VERSION ""

NS_ :

BS_:

BU_: AI JOYSTICK VCU OPUS RES

BO_ 3221225472 VECTOR__INDEPENDENT_SIG_MSG: 0 Vector__XXX
 SG_ VEHFAN_DO_V_UC : 0|1@1- (67,0) [0|67] "DO" Vector__XXX
 SG_ SCUFAN_FB_AI_V_UC : 0|1@1- (19,0) [0|19] "AI" Vector__XXX
 SG_ SCUFAN_DO_V_UC : 0|1@1- (11,0) [0|11] "DO" Vector__XXX
 SG_ CANC_CN_TX_DO_UC : 0|1@1- (95,0) [0|95] "CAN2_TX" Vector__XXX
 SG_ CANC_CN_STB_DO_UC : 0|1@1- (100,0) [0|100] "DO" Vector__XXX
 SG_ ISENSE_AI_A_UC : 0|1@1- (98,0) [0|98] "AI" Vector__XXX
 SG_ SCUFAN_PWM_PO_PC_UC : 0|1@1- (5,0) [0|5] "OC" Vector__XXX
 SG_ ASMS_DI_V_UC : 0|1@1- (3,0) [0|3] "DI" Vector__XXX
 SG_ CANB1_CN_STB_DO_UC : 0|1@1- (92,0) [0|92] "DO" Vector__XXX
 SG_ HVIL_EN_DO_V_UC : 0|1@1- (79,0) [0|79] "DO" Vector__XXX
 SG_ SPD2_FI_HZ_UC : 0|1@1- (77,0) [0|77] "IC" Vector__XXX
 SG_ HVIL_DI_V_UC : 0|1@1- (76,0) [0|76] "DI" Vector__XXX
 SG_ SPD4_FI_HZ_UC : 0|1@1- (72,0) [0|72] "IC" Vector__XXX
 SG_ SPD3_FI_HZ_UC : 0|1@1- (69,0) [0|69] "IC" Vector__XXX
 SG_ TSMS_DI_V_UC : 0|1@1- (66,0) [0|66] "DI" Vector__XXX
 SG_ DEN_DO_V_UC : 0|1@1- (60,0) [0|60] "DO" Vector__XXX
 SG_ DSEL_DO_V_UC : 0|1@1- (59,0) [0|59] "DO" Vector__XXX
 SG_ HVSPI_TX_DO_UC : 0|1@1- (53,0) [0|53] "HVSPI_TX" Vector__XXX
 SG_ HVSPI_CE_DO_UC : 0|1@1- (52,0) [0|52] "DO" Vector__XXX
 SG_ HVPOS2_DO_V_UC : 0|1@1- (50,0) [0|50] "DO" Vector__XXX
 SG_ CHG_EN_DO_V_UC : 0|1@1- (49,0) [0|49] "DO" Vector__XXX
 SG_ DCDCRLY_DO_V_UC : 0|1@1- (47,0) [0|47] "DO" Vector__XXX
 SG_ TEST_POINT_2_DO_UC : 0|1@1- (40,0) [0|40] "DO" Vector__XXX
 SG_ TEST_POINT_3_DO_UC : 0|1@1- (39,0) [0|39] "DO" Vector__XXX
 SG_ PRECHG_EN_DO_V_UC : 0|1@1- (41,0) [0|41] "DO" Vector__XXX
 SG_ DACSPI_CE_DO_UC_RG9 : 0|1@1- (14,0) [0|14] "DO" Vector__XXX
 SG_ UCLED_DO_V_UC : 0|1@1- (1,0) [0|1] "DO" Vector__XXX
 SG_ IVREF_AI_V_UC : 0|1@1- (93,0) [0|93] "AI" Vector__XXX
 SG_ CANC_CN_RX_DI_UC : 0|1@1- (91,0) [0|91] "CAN2_RX" Vector__XXX
 SG_ SPD1_FI_HZ_UC : 0|1@1- (81,0) [0|81] "IC" Vector__XXX
 SG_ HVPOS1_DO_V_UC : 0|1@1- (61,0) [0|61] "DO" Vector__XXX
 SG_ HVSPI_RX_DI_UC : 0|1@1- (58,0) [0|58] "HVSPI_RX" Vector__XXX
 SG_ HVSPI_CK_DO_UC : 0|1@1- (51,0) [0|51] "HVSPI_CK" Vector__XXX
 SG_ PUMP_DO_EN_V_UC : 0|1@1- (4,0) [0|4] "DO" Vector__XXX
 SG_ DACSPI_TX_DO_UC : 0|1@1- (12,0) [0|12] "SPITX" Vector__XXX
 SG_ DACSPI_CK_DO_UC : 0|1@1- (10,0) [0|10] "SPICK" Vector__XXX
 SG_ CANB1_CN_TX_DO_UC : 0|1@1- (89,0) [0|89] "CAN1_TX" Vector__XXX
 SG_ CANB1_CN_RX_DI_UC : 0|1@1- (90,0) [0|90] "CAN1_RX" Vector__XXX
 SG_ ISFB_AI_I_UC : 0|1@1- (44,0) [0|44] "AI" Vector__XXX
 SG_ ONOFF_DCDC_DO_V_UC : 0|1@1- (42,0) [0|42] "DO" Vector__XXX
 SG_ KL15_AI_V_UC : 0|1@1- (25,0) [0|25] "AI" Vector__XXX
 SG_ PSU_12V_AI_V_UC : 0|1@1- (24,0) [0|24] "AI" Vector__XXX
 SG_ E12V_AI_V_UC : 0|1@1- (23,0) [0|23] "AI" Vector__XXX
 SG_ PSU_5V_AI_V_UC : 0|1@1- (22,0) [0|22] "AI" Vector__XXX
 SG_ PSU_3V3_AI_V_UC : 0|1@1- (21,0) [0|21] "AI" Vector__XXX
 SG_ DCDCTEMP_AI_C_UC : 0|1@1- (20,0) [0|20] "AI" Vector__XXX
 SG_ ASSI_Y_DO_V_UC : 0|1@1- (9,0) [0|9] "DO" Vector__XXX
 SG_ ASSI_B_DO_V_UC : 0|1@1- (8,0) [0|8] "DO" Vector__XXX
 SG_ SIREN_DO_V_UC : 0|1@1- (7,0) [0|7] "DO" Vector__XXX
 SG_ DISPLAY_DO_V_UC : 0|1@1- (6,0) [0|6] "DO" Vector__XXX
 SG_ FRONT_AXLE_TRQ_REQUEST : 0|16@1+ (0.1,0) [0|195] "Nm" Vector__XXX
 SG_ FRONT_AXLE_TRQ_MAX : 0|16@1+ (0.1,0) [0|195] "Nm" Vector__XXX
 SG_ FRONT_AXLE_TRQ : 0|16@1- (0.1,0) [-195|195] "Nm" Vector__XXX
 SG_ FRONT_AXLE_TRQ_REQUEST : 0|16@1+ (0.1,0) [0|195] "Nm" Vector__XXX
 SG_ Yaw_rate_degps : 0|16@1- (0.0078125,0) [-256|255.992] "deg/s" Vector__XXX
 SG_ BRAKE_PLAUSIBILITY : 0|1@1- (1,0) [0|1] "__W__" Vector__XXX
 SG_ KL15_UNDER_V : 0|1@1- (1,0) [0|1] "__W__" Vector__XXX
 SG_ R1_AI2VCU_STATUS_HANDSHAKE_TIMEO : 0|1@1- (1,0) [0|1] "" Vector__XXX
 SG_ R1_AI2VCU_BRAKE_TIMEOUT_ERROR : 0|1@1- (1,0) [0|1] "" Vector__XXX
 SG_ R1_AI2VCU_STEER_TIMEOUT_ERROR : 0|1@1- (1,0) [0|1] "" Vector__XXX
 SG_ R1_AI2VCU_DRIVE_R_TIMEOUT_ERROR : 0|1@1- (1,0) [0|1] "" Vector__XXX
 SG_ R1_AI2VCU_DRIVE_F_TIMEOUT_ERROR : 0|1@1- (1,0) [0|1] "" Vector__XXX
 SG_ MISSION_STATUS : 0|1@1- (1,0) [0|1] "__W__" Vector__XXX
 SG_ AUTO_BRAKING : 0|1@1- (1,0) [0|1] "__W__" Vector__XXX
 SG_ AI_COMMS_LOST : 0|1@1- (1,0) [0|1] "__W__" Vector__XXX
 SG_ AI_ESTOP_REQ : 0|1@1- (1,0) [0|1] "__W__" Vector__XXX
 SG_ MISSION_RESET : 0|1@1- (1,0) [0|1] "" Vector__XXX
 SG_ SCRN_INHIBIT : 0|1@1- (1,0) [0|1] "" Vector__XXX
 SG_ DCDCRLY_REQ : 0|1@1- (1,0) [0|1] "" Vector__XXX
 SG_ R1_RES_TPDO_TIMEOUT_ERROR : 0|1@1- (1,0) [0|1] "" Vector__XXX
 SG_ DO_PUMP_EN : 0|1@1- (1,0) [0|1] "" Vector__XXX
 SG_ DO_HVIL_EN : 0|1@1- (1,0) [0|1] "" Vector__XXX
 SG_ DO_DCDC_ONOFF : 0|1@1- (1,0) [0|1] "" Vector__XXX
 SG_ R2_MCF2VC_TPDO1_TIMEOUT_ERROR : 0|1@1- (1,0) [0|1] "" Vector__XXX
 SG_ R2_MCR2VC_TPDO1_TIMEOUT_ERROR : 0|1@1- (1,0) [0|1] "" Vector__XXX
 SG_ R2_SC2VCU_STEER_TIMEOUT_ERROR : 0|1@1- (1,0) [0|1] "" Vector__XXX
 SG_ R1_AI2VCU_STATUS_TIMEOUT_ERROR : 0|1@1- (1,0) [0|1] "" Vector__XXX
 SG_ R1_UMB_PDO2_TIMEOUT_ERROR : 0|1@1- (1,0) [0|1] "" Vector__XXX
 SG_ REVERSE_POLARITY_FAULT : 0|1@1- (1,0) [0|1] "" Vector__XXX
 SG_ OVERTEMP_FAULT : 0|1@1- (1,0) [0|1] "" Vector__XXX
 SG_ INPUT_VOLTAGE_FAULT : 0|1@1- (1,0) [0|1] "" Vector__XXX
 SG_ HARDWARE_FAULT : 0|1@1- (1,0) [0|1] "" Vector__XXX
 SG_ COMMS_FAULT : 0|1@1- (1,0) [0|1] "" Vector__XXX
 SG_ WARN_UNDER_VOLT : 0|1@1- (1,0) [0|1] "" Vector__XXX
 SG_ DCDC_EN_STATUS : 0|1@1- (1,0) [0|1] "" Vector__XXX
 SG_ FAULT_CHARGER_FAULTS : 0|1@1- (1,0) [0|1] "" Vector__XXX
 SG_ WARNING_LOW_SOC : 0|1@1- (1,0) [0|1] "" Vector__XXX
 SG_ WARNING_TEMP_HIGH : 0|1@1- (1,0) [0|1] "" Vector__XXX
 SG_ FAULT_MEASUREMENT : 0|1@1- (1,0) [0|1] "" Vector__XXX
 SG_ FAULT_FUSE_ACTIVATION : 0|1@1- (1,0) [0|1] "" Vector__XXX
 SG_ FAULT_PRECHG_OPEN : 0|1@1- (1,0) [0|1] "" Vector__XXX
 SG_ FAULT_HVPOS2_OPEN : 0|1@1- (1,0) [0|1] "" Vector__XXX
 SG_ FAULT_HVPOS1_OPEN : 0|1@1- (1,0) [0|1] "" Vector__XXX
 SG_ FAULT_CHG_AUX_SHORT : 0|1@1- (1,0) [0|1] "" Vector__XXX
 SG_ FAULT_CHG_AUX_OPEN : 0|1@1- (1,0) [0|1] "" Vector__XXX
 SG_ FAULT_LOW_SOC : 0|1@1- (1,0) [0|1] "" Vector__XXX
 SG_ FAULT_VOLTAGE_DISAGREE : 0|1@1- (1,0) [0|1] "" Vector__XXX
 SG_ FAULT_OVER_CURRENT : 0|1@1- (1,0) [0|1] "" Vector__XXX
 SG_ FAULT_CELL_UNDER_VOLT : 0|1@1- (1,0) [0|1] "" Vector__XXX
 SG_ FAULT_CELL_OVER_VOLT : 0|1@1- (1,0) [0|1] "" Vector__XXX
 SG_ FAULT_CELL_OVER_TEMP : 0|1@1- (1,0) [0|1] "" Vector__XXX
 SG_ BMS_FAULT_FLAG : 0|1@1- (1,0) [0|1] "" Vector__XXX
 SG_ HVNEG_STATUS : 0|1@1- (1,0) [0|1] "" Vector__XXX
 SG_ DSEL_DO_V_UC_RA3 : 0|1@1- (1,0) [0|1] "" Vector__XXX
 SG_ DEN_DO_V_UC_RA4 : 0|1@1- (1,0) [0|1] "" Vector__XXX
 SG_ HVPOS2_DO_V_UC_RF5 : 0|1@1- (1,0) [0|1] "" Vector__XXX
 SG_ CHG_EN_DO_V_UC_RF4 : 0|1@1- (1,0) [0|1] "" Vector__XXX
 SG_ PRECHARGE_EN_DO_V_UC_RB12 : 0|1@1- (1,0) [0|1] "" Vector__XXX
 SG_ HVPOS1_DO_V_UC_RA5 : 0|1@1- (1,0) [0|1] "" Vector__XXX
 SG_ ASMS_DI_V_UC_RE5 : 0|1@1- (1,0) [0|1] "" Vector__XXX
 SG_ SPD3_F1_HZ_UC_RD9 : 0|1@1- (1,0) [0|1] "" Vector__XXX
 SG_ SPD1_F1_HZ_UC_RD4 : 0|1@1- (1,0) [0|1] "" Vector__XXX
 SG_ SPD2_F1_HZ_UC_RD2 : 0|1@1- (1,0) [0|1] "" Vector__XXX
 SG_ HVIL_DI_V_UC_RD1 : 0|1@1- (1,0) [0|1] "" Vector__XXX
 SG_ SPD4_F1_HZ_UC_RD0 : 0|1@1- (1,0) [0|1] "" Vector__XXX
 SG_ TSMS_DI_V_UC_RA14 : 0|1@1- (1,0) [0|1] "" Vector__XXX
 SG_ VEHFAN_DO_V_UC_RA15 : 0|1@1- (1,0) [0|1] "" Vector__XXX
 SG_ DCDCRLY_DO_V_UC_RD14 : 0|1@1- (1,0) [0|1] "" Vector__XXX
 SG_ BMS_CAN_STOP : 0|1@1- (1,0) [0|1] "" Vector__XXX
 SG_ UCLED_DO_V_UC_RG15 : 0|1@1- (1,0) [0|1] "" Vector__XXX
 SG_ EBSLED_DO_V_UC_RE7 : 0|1@1- (1,0) [0|1] "" Vector__XXX
 SG_ PUMP_DO_V_UC_RE6 : 0|1@1- (1,0) [0|1] "" Vector__XXX
 SG_ HVNEG_EN_DO_V_UC_RD15 : 0|1@1- (1,0) [0|1] "" Vector__XXX
 SG_ HVIL_EN_DO_V_UC_RD12 : 0|1@1- (1,0) [0|1] "" Vector__XXX
 SG_ ASSI_Y_DO_V_UC_RC4 : 0|1@1- (1,0) [0|1] "" Vector__XXX
 SG_ ASSI_B_DO_V_UC_RC3 : 0|1@1- (1,0) [0|1] "" Vector__XXX
 SG_ SIREN_DO_V_UC_RC2 : 0|1@1- (1,0) [0|1] "" Vector__XXX
 SG_ DISPLAY_DO_V_UC_RC1 : 0|1@1- (1,0) [0|1] "" Vector__XXX
 SG_ ONOFF_DCDC_DO_V_UC_RB13 : 0|1@1- (1,0) [0|1] "" Vector__XXX
 SG_ DSEL_DO_V_UC_RA3 : 0|1@1- (1,0) [0|1] "" Vector__XXX

BO_ 0 NMT: 2 VCU
 SG_ CMD : 0|8@1+ (1,0) [0|255] ""  OPUS,RES,JOYSTICK
 SG_ NODE_ID : 8|8@1+ (1,0) [0|255] ""  OPUS,RES,JOYSTICK

BO_ 1312 VCU2AI_Status: 8 VCU
 SG_ BRAKE_PLAUSIBILITY_FAULT : 50|1@1- (1,0) [0|1] "__F__"  AI,OPUS
 SG_ BMS_FAULT : 49|1@1- (1,0) [0|1] "__F__"  AI,OPUS
 SG_ SHUTDOWN_CAUSE : 56|8@1+ (1,0) [0|255] ""  AI,OPUS
 SG_ MISSION_STATUS_FAULT : 47|1@1- (1,0) [0|1] "__F__"  AI,OPUS
 SG_ AUTONOMOUS_BRAKING_FAULT : 46|1@1- (1,0) [0|1] "__F__"  AI,OPUS
 SG_ CHARGE_PROCEDURE_FAULT : 48|1@1- (1,0) [0|1] "__F__"  AI,OPUS
 SG_ WARN_BATT_SOC_LOW : 33|1@1- (1,0) [0|1] ""  AI,OPUS
 SG_ WARN_BATT_TEMP_HIGH : 32|1@1- (1,0) [0|1] ""  AI,OPUS
 SG_ AI_COMMS_LOST : 45|1@1- (1,0) [0|1] "__F__"  AI,OPUS
 SG_ OFFBOARD_CHARGER_FAULT : 44|1@1- (1,0) [0|1] "__F__"  AI,OPUS
 SG_ EBS_FAULT : 43|1@1- (1,0) [0|1] "__F__"  AI,OPUS
 SG_ HVIL_SHORT_FAULT : 42|1@1- (1,0) [0|1] "__F__"  AI,OPUS
 SG_ HVIL_OPEN_FAULT : 41|1@1- (1,0) [0|1] "__F__"  AI,OPUS
 SG_ AI_ESTOP_REQUEST : 40|1@1- (1,0) [0|1] "__F__"  AI,OPUS
 SG_ GO_SIGNAL : 11|1@1- (1,0) [0|1] ""  AI,OPUS
 SG_ AMI_STATE : 20|4@1+ (1,0) [0|15] ""  AI,OPUS
 SG_ HANDSHAKE : 0|1@1- (1,0) [0|1] ""  AI,OPUS
 SG_ WARNING_STATUS : 25|1@1- (1,0) [0|1] ""  AI,OPUS
 SG_ FAULT_STATUS : 24|1@1- (1,0) [0|1] ""  AI,OPUS
 SG_ SHUTDOWN_REQUEST : 8|1@1- (1,0) [0|1] ""  AI,OPUS
 SG_ STEERING_STATUS : 12|2@1+ (1,0) [0|3] ""  AI,OPUS
 SG_ AS_STATE : 16|4@1+ (1,0) [0|7] ""  AI,OPUS
 SG_ TS_SWITCH_STATUS : 10|1@1- (1,0) [0|1] ""  AI,OPUS
 SG_ AS_SWITCH_STATUS : 9|1@1- (1,0) [0|1] ""  AI,OPUS

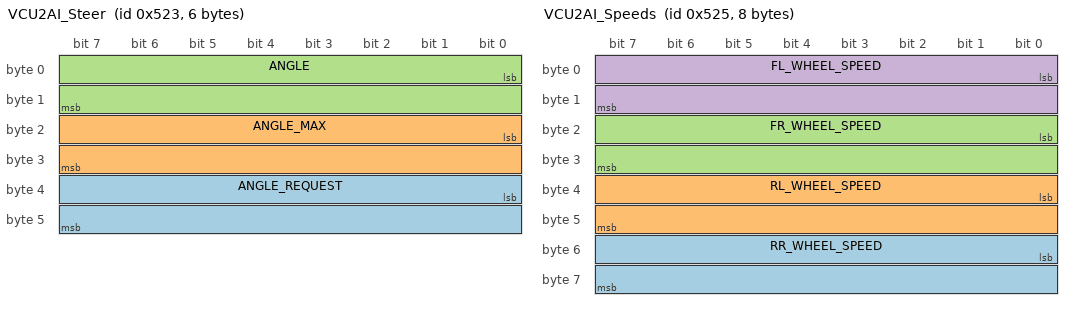
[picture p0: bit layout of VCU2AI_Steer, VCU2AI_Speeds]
BO_ 1315 VCU2AI_Steer: 6 VCU
 SG_ ANGLE_REQUEST : 32|16@1- (0.1,0) [-21|21] "deg"  AI,OPUS
 SG_ ANGLE_MAX : 16|16@1+ (0.1,0) [0|21] "deg"  AI,OPUS
 SG_ ANGLE : 0|16@1- (0.1,0) [-21|21] "deg"  AI,OPUS

BO_ 1317 VCU2AI_Speeds: 8 VCU
 SG_ RR_WHEEL_SPEED : 48|16@1+ (1,0) [0|1250] "rpm"  AI,OPUS
 SG_ RL_WHEEL_SPEED : 32|16@1+ (1,0) [0|1250] "rpm"  AI,OPUS
 SG_ FR_WHEEL_SPEED : 16|16@1+ (1,0) [0|1250] "rpm"  AI,OPUS
 SG_ FL_WHEEL_SPEED : 0|16@1+ (1,0) [0|1250] "rpm"  AI,OPUS

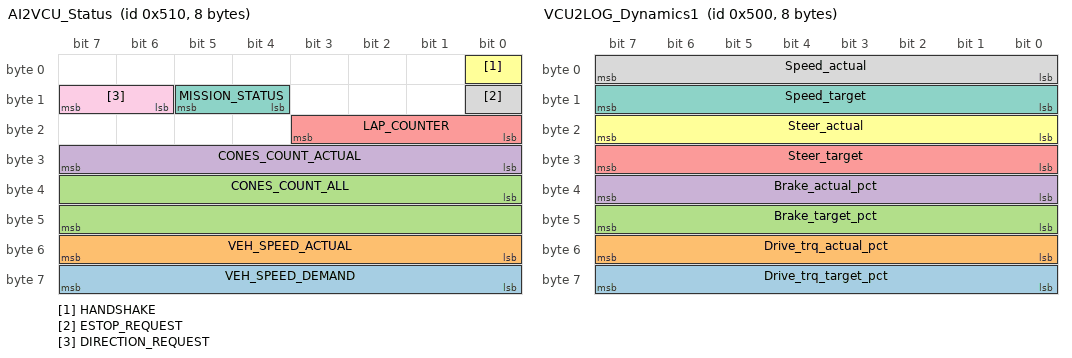
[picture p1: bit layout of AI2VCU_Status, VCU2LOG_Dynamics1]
BO_ 1296 AI2VCU_Status: 8 AI
 SG_ VEH_SPEED_DEMAND : 56|8@1+ (1,0) [0|255] "km/h"  OPUS,VCU
 SG_ VEH_SPEED_ACTUAL : 48|8@1+ (1,0) [0|255] "km/h"  OPUS,VCU
 SG_ CONES_COUNT_ALL : 32|16@1+ (1,0) [0|65535] ""  OPUS,VCU
 SG_ CONES_COUNT_ACTUAL : 24|8@1+ (1,0) [0|255] ""  OPUS,VCU
 SG_ LAP_COUNTER : 16|4@1+ (1,0) [0|15] ""  OPUS,VCU
 SG_ HANDSHAKE : 0|1@1- (1,0) [0|1] ""  OPUS,VCU
 SG_ MISSION_STATUS : 12|2@1+ (1,0) [0|3] ""  OPUS,VCU
 SG_ ESTOP_REQUEST : 8|1@1- (1,0) [0|1] ""  OPUS,VCU
 SG_ DIRECTION_REQUEST : 14|2@1+ (1,0) [0|3] ""  OPUS,VCU

BO_ 1280 VCU2LOG_Dynamics1: 8 VCU
 SG_ Drive_trq_target_pct : 56|8@1+ (1,0) [0|100] "%"  OPUS
 SG_ Drive_trq_actual_pct : 48|8@1+ (1,0) [0|100] "%"  OPUS
 SG_ Brake_target_pct : 40|8@1+ (1,0) [0|100] "%"  OPUS
 SG_ Brake_actual_pct : 32|8@1+ (1,0) [0|100] "%"  OPUS
 SG_ Steer_target : 24|8@1- (0.5,0) [-64|63.5] "deg"  OPUS
 SG_ Steer_actual : 16|8@1- (0.5,0) [-64|63.5] "deg"  OPUS
 SG_ Speed_target : 8|8@1+ (1,0) [0|255] "km/h"  OPUS
 SG_ Speed_actual : 0|8@1+ (1,0) [0|255] "km/h"  OPUS

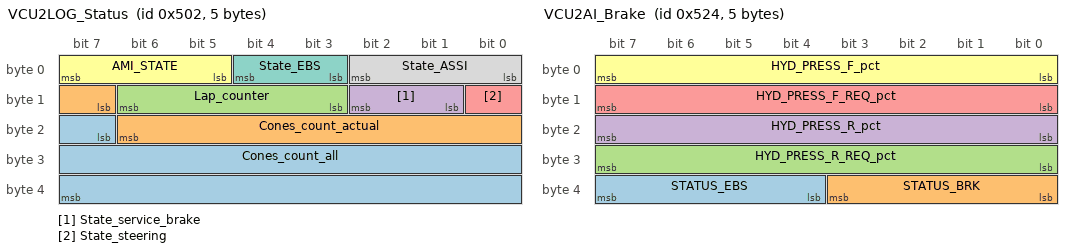
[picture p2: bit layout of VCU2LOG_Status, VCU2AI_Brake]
BO_ 1282 VCU2LOG_Status: 5 VCU
 SG_ Cones_count_all : 23|17@1+ (1,0) [0|131071] ""  OPUS
 SG_ Cones_count_actual : 15|8@1+ (1,0) [0|255] ""  OPUS
 SG_ Lap_counter : 11|4@1+ (1,0) [0|15] ""  OPUS
 SG_ State_service_brake : 9|2@1+ (1,0) [0|3] ""  OPUS
 SG_ State_steering : 8|1@1- (1,0) [0|1] ""  OPUS
 SG_ AMI_STATE : 5|3@1+ (1,0) [0|7] ""  OPUS
 SG_ State_EBS : 3|2@1+ (1,0) [0|3] ""  OPUS
 SG_ State_ASSI : 0|3@1+ (1,0) [0|7] ""  OPUS

BO_ 1299 AI2VCU_Steer: 2 AI
 SG_ STEER_REQUEST : 0|16@1- (0.1,0) [-21|21] "deg"  OPUS,VCU

BO_ 1300 AI2VCU_Brake: 2 AI
 SG_ HYD_PRESS_R_REQ_pct : 8|8@1+ (0.5,0) [0|100] "%"  OPUS,VCU
 SG_ HYD_PRESS_F_REQ_pct : 0|8@1+ (0.5,0) [0|100] "%"  OPUS,VCU

BO_ 1316 VCU2AI_Brake: 5 VCU
 SG_ STATUS_EBS : 36|4@1+ (1,0) [0|15] ""  AI,OPUS
 SG_ STATUS_BRK : 32|4@1+ (1,0) [0|15] ""  AI,OPUS
 SG_ HYD_PRESS_R_REQ_pct : 24|8@1+ (0.5,0) [0|100] "%"  AI,OPUS
 SG_ HYD_PRESS_R_pct : 16|8@1+ (0.5,0) [0|100] "%"  AI,OPUS
 SG_ HYD_PRESS_F_REQ_pct : 8|8@1+ (0.5,0) [0|100] "%"  AI,OPUS
 SG_ HYD_PRESS_F_pct : 0|8@1+ (0.5,0) [0|100] "%"  AI,OPUS

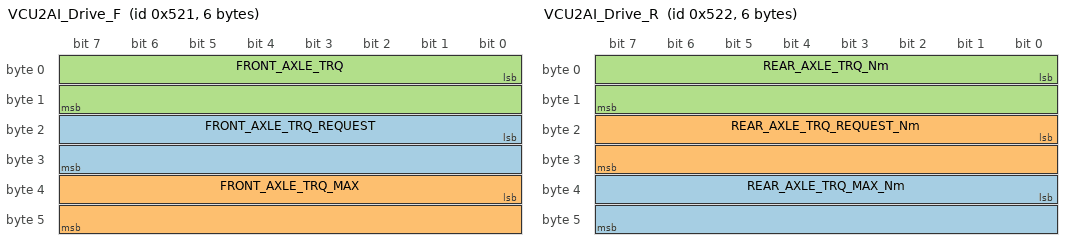
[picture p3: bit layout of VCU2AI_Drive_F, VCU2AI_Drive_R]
BO_ 1313 VCU2AI_Drive_F: 6 VCU
 SG_ FRONT_AXLE_TRQ_REQUEST : 16|16@1+ (0.1,0) [0|195] "Nm"  AI
 SG_ FRONT_AXLE_TRQ_MAX : 32|16@1+ (0.1,0) [0|195] "Nm"  AI
 SG_ FRONT_AXLE_TRQ : 0|16@1- (0.1,0) [-195|195] "Nm"  AI

BO_ 1297 AI2VCU_Drive_F: 4 AI
 SG_ FRONT_MOTOR_SPEED_MAX : 16|16@1+ (1,0) [0|4000] "rpm"  VCU
 SG_ FRONT_AXLE_TRQ_REQUEST : 0|16@1+ (0.1,0) [0|195] "Nm"  VCU

BO_ 1298 AI2VCU_Drive_R: 4 AI
 SG_ REAR_MOTOR_SPEED_MAX : 16|16@1+ (1,0) [0|4000] "rpm"  OPUS,VCU
 SG_ REAR_AXLE_TRQ_REQUEST : 0|16@1+ (0.1,0) [0|195] "Nm"  OPUS,VCU

BO_ 1314 VCU2AI_Drive_R: 6 VCU
 SG_ REAR_AXLE_TRQ_MAX_Nm : 32|16@1+ (0.1,0) [0|195] "Nm"  AI,OPUS
 SG_ REAR_AXLE_TRQ_REQUEST_Nm : 16|16@1+ (0.1,0) [0|195] "Nm"  AI,OPUS
 SG_ REAR_AXLE_TRQ_Nm : 0|16@1- (0.1,0) [-195|195] "Nm"  AI,OPUS

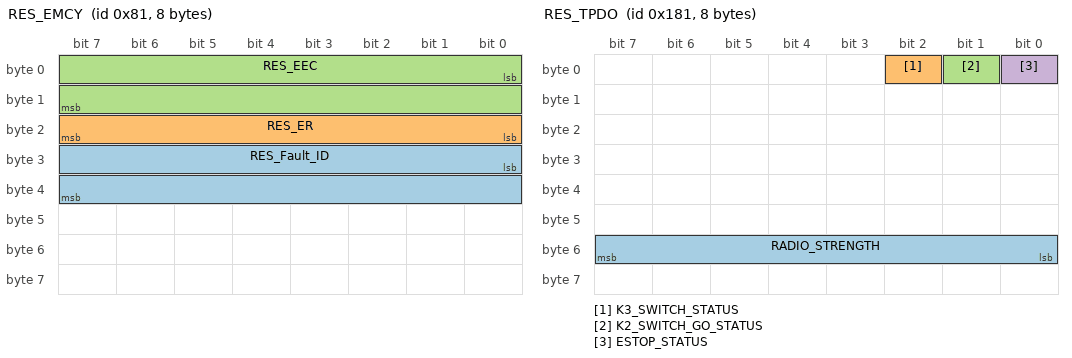
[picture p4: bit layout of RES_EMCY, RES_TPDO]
BO_ 129 RES_EMCY: 8 RES
 SG_ RES_Fault_ID : 24|16@1+ (1,0) [0|65535] ""  OPUS,VCU
 SG_ RES_ER : 16|8@1+ (1,0) [0|255] ""  OPUS,VCU
 SG_ RES_EEC : 0|16@1+ (1,0) [0|65535] ""  OPUS,VCU

BO_ 385 RES_TPDO: 8 RES
 SG_ RADIO_STRENGTH : 48|8@1+ (1,0) [0|255] "%"  OPUS,VCU
 SG_ K3_SWITCH_STATUS : 2|1@1- (1,0) [0|1] ""  OPUS,VCU
 SG_ K2_SWITCH_GO_STATUS : 1|1@1- (1,0) [0|1] ""  OPUS,VCU
 SG_ ESTOP_STATUS : 0|1@1- (1,0) [0|1] ""  OPUS,VCU

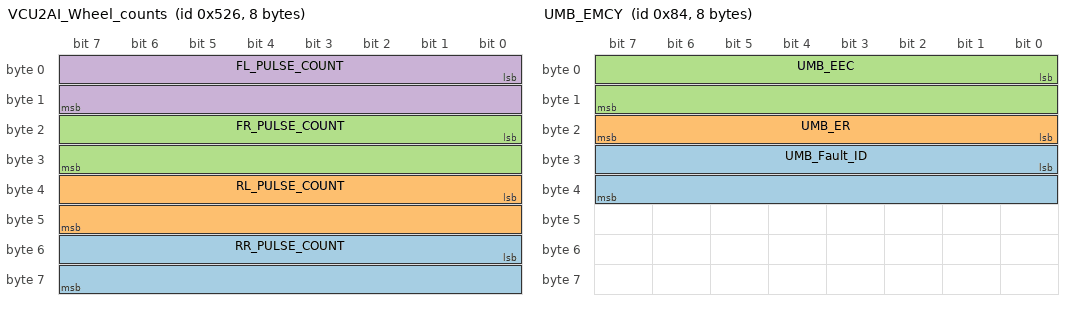
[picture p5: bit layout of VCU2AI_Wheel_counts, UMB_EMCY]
BO_ 1318 VCU2AI_Wheel_counts: 8 VCU
 SG_ RR_PULSE_COUNT : 48|16@1+ (1,0) [0|65535] ""  AI,OPUS
 SG_ RL_PULSE_COUNT : 32|16@1+ (1,0) [0|65535] ""  AI,OPUS
 SG_ FR_PULSE_COUNT : 16|16@1+ (1,0) [0|65535] ""  AI,OPUS
 SG_ FL_PULSE_COUNT : 0|16@1+ (1,0) [0|65535] ""  AI,OPUS

BO_ 291 OPUS2VCU_FB: 1 OPUS
 SG_ BRK_DISCH_REQ : 4|1@1- (1,0) [0|1] ""  VCU
 SG_ AMI_STATE : 0|4@1+ (1,0) [0|15] ""  VCU

BO_ 644 UMB_PDO2: 4 JOYSTICK
 SG_ XPOS : 16|16@1+ (1,0) [0|255] ""  OPUS,VCU
 SG_ YPOS : 0|16@1+ (1,0) [0|255] ""  OPUS,VCU

BO_ 132 UMB_EMCY: 8 JOYSTICK
 SG_ UMB_Fault_ID : 24|16@1+ (1,0) [0|65535] ""  OPUS,VCU
 SG_ UMB_ER : 16|8@1+ (1,0) [0|255] ""  OPUS,VCU
 SG_ UMB_EEC : 0|16@1+ (1,0) [0|65535] ""  OPUS,VCU

BO_ 128 SYNC: 0 VCU

BO_ 388 UMB_PDO1: 2 JOYSTICK
 SG_ BTN_BTM : 3|1@1- (1,0) [0|1] ""  OPUS,VCU
 SG_ BTN_TOP : 0|1@1- (1,0) [0|1] ""  OPUS,VCU

CM_ BU_ AI "AI Computer (NVIDIA Drive PX2)";
CM_ BU_ JOYSTICK "Umbilical controller";
CM_ BU_ VCU "Vehicle Control Unit";
CM_ BU_ OPUS "Display screen";
CM_ BU_ RES "Remote Emergency Stop";
CM_ BO_ 3221225472 "This is a message for not used signals, created by Vector CANdb++ DBC OLE DB Provider.";
CM_ SG_ 3221225472 ASMS_DI_V_UC "AN31/PWM4H/PMD7/RP87/RE7";
CM_ SG_ 3221225472 FRONT_AXLE_TRQ_REQUEST "Requested front axle torqueRequested front axle torque";
CM_ SG_ 3221225472 FRONT_AXLE_TRQ_MAX "Maximum front axle drive torque";
CM_ SG_ 3221225472 FRONT_AXLE_TRQ "Current front axle torque";
CM_ SG_ 3221225472 BRAKE_PLAUSIBILITY "Warning brake plausibility";
CM_ SG_ 3221225472 KL15_UNDER_V "Warning KL15 under voltage";
CM_ SG_ 3221225472 MISSION_STATUS "Warning Mission Status";
CM_ SG_ 3221225472 AUTO_BRAKING "Warning Auto Breaking";
CM_ SG_ 3221225472 AI_COMMS_LOST "Warning AI comms lost";
CM_ SG_ 3221225472 AI_ESTOP_REQ "Warning Estop Request";
CM_ SG_ 1312 BRAKE_PLAUSIBILITY_FAULT "Brake plausibility fault";
CM_ SG_ 1312 BMS_FAULT "BMS fault detected";
CM_ SG_ 1312 SHUTDOWN_CAUSE "Enumerated list of shutdown faults";
CM_ SG_ 1312 MISSION_STATUS_FAULT "Autonomous mission status fault";
CM_ SG_ 1312 AUTONOMOUS_BRAKING_FAULT "Braking in Autonomous Driving mode fault";
CM_ SG_ 1312 CHARGE_PROCEDURE_FAULT "Battery charging procedure fault";
CM_ SG_ 1312 WARN_BATT_SOC_LOW "Low traction battery SOC warning";
CM_ SG_ 1312 WARN_BATT_TEMP_HIGH "High traction battery temperature warning";
CM_ SG_ 1312 AI_COMMS_LOST "AI CAN communications fault";
CM_ SG_ 1312 OFFBOARD_CHARGER_FAULT "Offboard charger fault";
CM_ SG_ 1312 EBS_FAULT "EBS fault";
CM_ SG_ 1312 HVIL_SHORT_FAULT "HVIL short-circuit fault";
CM_ SG_ 1312 HVIL_OPEN_FAULT "HVIL open-circuit fault";
CM_ SG_ 1312 AI_ESTOP_REQUEST "AI system E-stop request";
CM_ SG_ 1312 GO_SIGNAL "Autonomous System \"Go\" signal";
CM_ SG_ 1312 AMI_STATE "State of the Mission Indicator";
CM_ SG_ 1312 HANDSHAKE "Handshake";
CM_ SG_ 1312 WARNING_STATUS "System warning status";
CM_ SG_ 1312 FAULT_STATUS "System fault status";
CM_ SG_ 1312 SHUTDOWN_REQUEST "Shutdown request to AI";
CM_ SG_ 1312 STEERING_STATUS "State of the steering system";
CM_ SG_ 1312 AS_STATE "State of the Autonomous System";
CM_ SG_ 1312 TS_SWITCH_STATUS "Tractive System switch status";
CM_ SG_ 1312 AS_SWITCH_STATUS "Autonomous System switch status";
CM_ SG_ 1315 ANGLE_REQUEST "Steer Angle Request";
CM_ SG_ 1315 ANGLE_MAX "Steer Angle Max";
CM_ SG_ 1315 ANGLE "Steer Angle";
CM_ SG_ 1296 CONES_COUNT_ALL "Total number of cones detected";
CM_ SG_ 1296 CONES_COUNT_ACTUAL "Number of cones detected";
CM_ SG_ 1296 LAP_COUNTER "Lap counter";
CM_ SG_ 1296 HANDSHAKE "Handshake";
CM_ SG_ 1296 MISSION_STATUS "Autonomous mission status";
CM_ SG_ 1296 ESTOP_REQUEST "Shutdown request to VCU";
CM_ SG_ 1296 DIRECTION_REQUEST "Requested vehicle direction";
CM_ SG_ 1300 HYD_PRESS_R_REQ_pct "Requested rear axle hydraulic brake pressure";
CM_ SG_ 1300 HYD_PRESS_F_REQ_pct "Requested front axle hydraulic brake pressure";
CM_ SG_ 1316 STATUS_EBS "Emergency brake status";
CM_ SG_ 1316 STATUS_BRK "Braking system status";
CM_ SG_ 1316 HYD_PRESS_R_REQ_pct "Requested rear axle hydraulic brake pressure";
CM_ SG_ 1316 HYD_PRESS_R_pct "Rear axle hydraulic brake pressure";
CM_ SG_ 1316 HYD_PRESS_F_REQ_pct "Requested front axle hydraulic brake pressure";
CM_ SG_ 1316 HYD_PRESS_F_pct "Front axle hydraulic brake pressure";
CM_ SG_ 1298 REAR_AXLE_TRQ_REQUEST "Requested rear axle torque";
CM_ SG_ 1314 REAR_AXLE_TRQ_MAX_Nm "Maximum rear axle drive torque";
CM_ SG_ 1314 REAR_AXLE_TRQ_REQUEST_Nm "Requested rear axle torque";
CM_ SG_ 1314 REAR_AXLE_TRQ_Nm "Current rear axle torque";
CM_ SG_ 1318 RR_PULSE_COUNT "Rear right wheel speed pulse count";
CM_ SG_ 1318 RL_PULSE_COUNT "Rear left wheel speed pulse count";
CM_ SG_ 1318 FR_PULSE_COUNT "Front right wheel speed pulse count";
CM_ SG_ 1318 FL_PULSE_COUNT "Front left wheel speed pulse count";
BA_DEF_  "BusType" STRING ;
BA_DEF_  "GenEnvVarEndingDsp" STRING ;
BA_DEF_  "GenEnvVarEndingSnd" STRING ;
BA_DEF_  "GenEnvVarPrefix" STRING ;
BA_DEF_ BU_  "GenNodAutoGenSnd" ENUM  "No","Yes";
BA_DEF_ BU_  "GenNodAutoGenDsp" ENUM  "No","Yes";
BA_DEF_ BO_  "GenMsgCycleTime" INT 0 10000;
BA_DEF_ SG_  "GenSigStartValue" FLOAT 1.17549E-038 3.4E+038;
BA_DEF_ SG_  "GenSigEnvVarType" ENUM  "int","float","undef";
BA_DEF_ SG_  "SystemSignalLongSymbol" STRING ;
BA_DEF_DEF_  "BusType" "CAN";
BA_DEF_DEF_  "GenEnvVarEndingDsp" "Dsp";
BA_DEF_DEF_  "GenEnvVarEndingSnd" "Snd";
BA_DEF_DEF_  "GenEnvVarPrefix" "Env";
BA_DEF_DEF_  "GenNodAutoGenSnd" "Yes";
BA_DEF_DEF_  "GenNodAutoGenDsp" "Yes";
BA_DEF_DEF_  "GenMsgCycleTime" 5;
BA_DEF_DEF_  "GenSigStartValue" 1.17549E-038;
BA_DEF_DEF_  "GenSigEnvVarType" "undef";
BA_DEF_DEF_  "SystemSignalLongSymbol" "";
BA_ "GenMsgCycleTime" BO_ 0 100;
BA_ "GenMsgCycleTime" BO_ 1312 10;
BA_ "GenMsgCycleTime" BO_ 1315 10;
BA_ "GenMsgCycleTime" BO_ 1317 10;
BA_ "GenMsgCycleTime" BO_ 1296 10;
BA_ "GenMsgCycleTime" BO_ 1280 100;
BA_ "GenMsgCycleTime" BO_ 1282 100;
BA_ "GenMsgCycleTime" BO_ 1299 10;
BA_ "GenMsgCycleTime" BO_ 1300 10;
BA_ "GenMsgCycleTime" BO_ 1316 10;
BA_ "GenMsgCycleTime" BO_ 1313 10;
BA_ "GenMsgCycleTime" BO_ 1297 10;
BA_ "GenMsgCycleTime" BO_ 1298 10;
BA_ "GenMsgCycleTime" BO_ 1314 10;
BA_ "GenMsgCycleTime" BO_ 129 10;
BA_ "GenMsgCycleTime" BO_ 385 10;
BA_ "GenMsgCycleTime" BO_ 1318 10;
BA_ "GenMsgCycleTime" BO_ 291 100;
BA_ "GenMsgCycleTime" BO_ 644 100;
BA_ "GenMsgCycleTime" BO_ 132 100;
BA_ "GenSigStartValue" SG_ 3221225472 FRONT_AXLE_TRQ_REQUEST 0;
BA_ "GenSigStartValue" SG_ 3221225472 FRONT_AXLE_TRQ_MAX 0;
BA_ "GenSigStartValue" SG_ 3221225472 FRONT_AXLE_TRQ 0;
BA_ "GenSigStartValue" SG_ 3221225472 Yaw_rate_degps 0;
BA_ "SystemSignalLongSymbol" SG_ 3221225472 R1_AI2VCU_STATUS_HANDSHAKE_TIMEO "R1_AI2VCU_STATUS_HANDSHAKE_TIMEOUT_ERROR";
BA_ "GenSigStartValue" SG_ 1312 AMI_STATE 0;
BA_ "GenSigStartValue" SG_ 1312 HANDSHAKE 0;
BA_ "GenSigStartValue" SG_ 1312 WARNING_STATUS 0;
BA_ "GenSigStartValue" SG_ 1312 FAULT_STATUS 0;
BA_ "GenSigStartValue" SG_ 1312 SHUTDOWN_REQUEST 0;
BA_ "GenSigStartValue" SG_ 1312 STEERING_STATUS 0;
BA_ "GenSigStartValue" SG_ 1312 AS_STATE 0;
BA_ "GenSigStartValue" SG_ 1312 TS_SWITCH_STATUS 0;
BA_ "GenSigStartValue" SG_ 1312 AS_SWITCH_STATUS 0;
BA_ "GenSigStartValue" SG_ 1296 CONES_COUNT_ALL 0;
BA_ "GenSigStartValue" SG_ 1296 CONES_COUNT_ACTUAL 0;
BA_ "GenSigStartValue" SG_ 1296 LAP_COUNTER 0;
BA_ "GenSigStartValue" SG_ 1296 HANDSHAKE 0;
BA_ "GenSigStartValue" SG_ 1296 MISSION_STATUS 0;
BA_ "GenSigStartValue" SG_ 1296 ESTOP_REQUEST 0;
BA_ "GenSigStartValue" SG_ 1296 DIRECTION_REQUEST 0;
BA_ "GenSigStartValue" SG_ 1280 Drive_trq_target_pct 0;
BA_ "GenSigStartValue" SG_ 1280 Drive_trq_actual_pct 0;
BA_ "GenSigStartValue" SG_ 1280 Brake_target_pct 0;
BA_ "GenSigStartValue" SG_ 1280 Brake_actual_pct 0;
BA_ "GenSigStartValue" SG_ 1282 Cones_count_all 0;
BA_ "GenSigStartValue" SG_ 1282 Cones_count_actual 0;
BA_ "GenSigStartValue" SG_ 1282 Lap_counter 0;
BA_ "GenSigStartValue" SG_ 1282 State_service_brake 0;
BA_ "GenSigStartValue" SG_ 1282 State_steering 0;
BA_ "GenSigStartValue" SG_ 1282 AMI_STATE 0;
BA_ "GenSigStartValue" SG_ 1282 State_EBS 0;
BA_ "GenSigStartValue" SG_ 1282 State_ASSI 0;
BA_ "GenSigStartValue" SG_ 1300 HYD_PRESS_F_REQ_pct 0;
BA_ "GenSigStartValue" SG_ 1316 HYD_PRESS_F_REQ_pct 0;
BA_ "GenSigStartValue" SG_ 1316 HYD_PRESS_F_pct 0;
BA_ "GenSigStartValue" SG_ 1298 REAR_AXLE_TRQ_REQUEST 0;
BA_ "GenSigStartValue" SG_ 1314 REAR_AXLE_TRQ_MAX_Nm 0;
BA_ "GenSigStartValue" SG_ 1314 REAR_AXLE_TRQ_REQUEST_Nm 0;
BA_ "GenSigStartValue" SG_ 1314 REAR_AXLE_TRQ_Nm 0;
VAL_ 3221225472 BRAKE_PLAUSIBILITY 1 "TRUE" 0 "FALSE" ;
VAL_ 3221225472 R1_AI2VCU_STATUS_HANDSHAKE_TIMEO 1 "TRUE" 0 "FALSE" ;
VAL_ 3221225472 R1_AI2VCU_BRAKE_TIMEOUT_ERROR 1 "TRUE" 0 "FALSE" ;
VAL_ 3221225472 R1_AI2VCU_STEER_TIMEOUT_ERROR 1 "TRUE" 0 "FALSE" ;
VAL_ 3221225472 R1_AI2VCU_DRIVE_R_TIMEOUT_ERROR 1 "TRUE" 0 "FALSE" ;
VAL_ 3221225472 R1_AI2VCU_DRIVE_F_TIMEOUT_ERROR 1 "TRUE" 0 "FALSE" ;
VAL_ 3221225472 MISSION_STATUS 1 "TRUE" 0 "FALSE" ;
VAL_ 3221225472 AUTO_BRAKING 1 "TRUE" 0 "FALSE" ;
VAL_ 3221225472 AI_COMMS_LOST 1 "TRUE" 0 "FALSE" ;
VAL_ 3221225472 AI_ESTOP_REQ 1 "TRUE" 0 "FALSE" ;
VAL_ 3221225472 MISSION_RESET 1 "TRUE" 0 "FALSE" ;
VAL_ 3221225472 SCRN_INHIBIT 1 "TRUE" 0 "FALSE" ;
VAL_ 3221225472 DCDCRLY_REQ 1 "CLOSE" 0 "OPEN" ;
VAL_ 3221225472 R1_RES_TPDO_TIMEOUT_ERROR 1 "TRUE" 0 "FALSE" ;
VAL_ 3221225472 DO_PUMP_EN 1 "ON" 0 "OFF" ;
VAL_ 3221225472 DO_HVIL_EN 1 "ON" 0 "OFF" ;
VAL_ 3221225472 DO_DCDC_ONOFF 1 "ON" 0 "OFF" ;
VAL_ 3221225472 R2_MCF2VC_TPDO1_TIMEOUT_ERROR 1 "TRUE" 0 "FALSE" ;
VAL_ 3221225472 R2_MCR2VC_TPDO1_TIMEOUT_ERROR 1 "TRUE" 0 "FALSE" ;
VAL_ 3221225472 R2_SC2VCU_STEER_TIMEOUT_ERROR 1 "TRUE" 0 "FALSE" ;
VAL_ 3221225472 R1_AI2VCU_STATUS_TIMEOUT_ERROR 1 "TRUE" 0 "FALSE" ;
VAL_ 3221225472 R1_UMB_PDO2_TIMEOUT_ERROR 1 "TRUE" 0 "FALSE" ;
VAL_ 3221225472 WARN_UNDER_VOLT 1 "TRUE" 0 "FALSE" ;
VAL_ 3221225472 DCDC_EN_STATUS 1 "CLOSE" 0 "OPEN" ;
VAL_ 3221225472 FAULT_CHARGER_FAULTS 1 "FAULT DETECTED" 0 "NO FAULT" ;
VAL_ 3221225472 WARNING_LOW_SOC 1 "TRUE" 0 "FALSE" ;
VAL_ 3221225472 WARNING_TEMP_HIGH 1 "TRUE" 0 "FALSE" ;
VAL_ 3221225472 FAULT_MEASUREMENT 1 "TRUE" 0 "FALSE" ;
VAL_ 3221225472 FAULT_FUSE_ACTIVATION 1 "TRUE" 0 "FALSE" ;
VAL_ 3221225472 FAULT_PRECHG_OPEN 1 "TRUE" 0 "FALSE" ;
VAL_ 3221225472 FAULT_HVPOS2_OPEN 1 "TRUE" 0 "FALSE" ;
VAL_ 3221225472 FAULT_HVPOS1_OPEN 1 "TRUE" 0 "FALSE" ;
VAL_ 3221225472 FAULT_CHG_AUX_SHORT 1 "TRUE" 0 "FALSE" ;
VAL_ 3221225472 FAULT_CHG_AUX_OPEN 1 "TRUE" 0 "FALSE" ;
VAL_ 3221225472 FAULT_LOW_SOC 1 "TRUE" 0 "FALSE" ;
VAL_ 3221225472 FAULT_VOLTAGE_DISAGREE 1 "TRUE" 0 "FALSE" ;
VAL_ 3221225472 FAULT_OVER_CURRENT 1 "TRUE" 0 "FALSE" ;
VAL_ 3221225472 FAULT_CELL_UNDER_VOLT 1 "TRUE" 0 "FALSE" ;
VAL_ 3221225472 FAULT_CELL_OVER_VOLT 1 "TRUE" 0 "FALSE" ;
VAL_ 3221225472 FAULT_CELL_OVER_TEMP 1 "TRUE" 0 "FALSE" ;
VAL_ 3221225472 BMS_FAULT_FLAG 1 "TRUE" 0 "FALSE" ;
VAL_ 3221225472 HVNEG_STATUS 1 "FAULT DETECTED" 0 "NO FAULT" ;
VAL_ 3221225472 HVPOS2_DO_V_UC_RF5 1 "CLOSE" 0 "OPEN" ;
VAL_ 3221225472 CHG_EN_DO_V_UC_RF4 1 "CLOSE" 0 "OPEN" ;
VAL_ 3221225472 PRECHARGE_EN_DO_V_UC_RB12 1 "CLOSE" 0 "OPEN" ;
VAL_ 3221225472 HVPOS1_DO_V_UC_RA5 1 "CLOSE" 0 "OPEN" ;
VAL_ 0 CMD 130 "Reset communication" 129 "Reset node" 128 "Pre-operational" 2 "Stop" 1 "Start" ;
VAL_ 0 NODE_ID 4 "UMB_NODE" 1 "RES_NODE" 0 "ALL_NODES" ;
VAL_ 1312 BRAKE_PLAUSIBILITY_FAULT 1 "TRUE" 0 "FALSE" ;
VAL_ 1312 BMS_FAULT 1 "TRUE" 0 "FALSE" ;
VAL_ 1312 SHUTDOWN_CAUSE 10 "BMS_FAULT" 9 "CHARGE_PROCEDURE_FAULT" 8 "MISSION_STATUS_FAULT" 7 "AUTONOMOUS_BRAKING_FAULT" 6 "AI_COMMS_FAULT" 5 "OFFBOARD_CHARGER_FAULT" 4 "EBS_FAULT" 3 "HVIL_SHORT_FAULT" 2 "HVIL_OPEN_FAULT" 1 "AI_COMPUTER_REQUEST" 0 "NO_SHUTDOWN" ;
VAL_ 1312 MISSION_STATUS_FAULT 1 "TRUE" 0 "FALSE" ;
VAL_ 1312 AUTONOMOUS_BRAKING_FAULT 1 "TRUE" 0 "FALSE" ;
VAL_ 1312 CHARGE_PROCEDURE_FAULT 1 "TRUE" 0 "FALSE" ;
VAL_ 1312 WARN_BATT_SOC_LOW 1 "TRUE" 0 "FALSE" ;
VAL_ 1312 WARN_BATT_TEMP_HIGH 1 "TRUE" 0 "FALSE" ;
VAL_ 1312 AI_COMMS_LOST 1 "TRUE" 0 "FALSE" ;
VAL_ 1312 OFFBOARD_CHARGER_FAULT 1 "TRUE" 0 "FALSE" ;
VAL_ 1312 EBS_FAULT 1 "TRUE" 0 "FALSE" ;
VAL_ 1312 HVIL_SHORT_FAULT 1 "TRUE" 0 "FALSE" ;
VAL_ 1312 HVIL_OPEN_FAULT 1 "TRUE" 0 "FALSE" ;
VAL_ 1312 AI_ESTOP_REQUEST 1 "TRUE" 0 "FALSE" ;
VAL_ 1312 GO_SIGNAL 1 "GO" 0 "NO GO" ;
VAL_ 1312 AMI_STATE 7 "AUTONOMOUS DEMO" 6 "STATIC INSPECTION B" 5 "STATIC INSPECTION A" 4 "TRACK DRIVE" 3 "AUTOCROSS" 2 "SKIDPAD" 1 "ACCELERATION" 0 "NOT SELECTED" ;
VAL_ 1312 WARNING_STATUS 1 "WARNING ACTIVE" 0 "NO WARNING" ;
VAL_ 1312 FAULT_STATUS 1 "FAULT DETECTED" 0 "NO FAULT" ;
VAL_ 1312 SHUTDOWN_REQUEST 1 "SHUTDOWN REQUESTED" 0 "NO SHUTDOWN" ;
VAL_ 1312 STEERING_STATUS 1 "ACTIVE" 0 "OFF" ;
VAL_ 1312 AS_STATE 5 "AS_FINISHED" 4 "EMERGENCY_BRAKE" 3 "AS_DRIVING" 2 "AS_READY" 1 "AS_OFF" ;
VAL_ 1312 TS_SWITCH_STATUS 1 "ON" 0 "OFF" ;
VAL_ 1312 AS_SWITCH_STATUS 1 "ON" 0 "OFF" ;
VAL_ 1296 MISSION_STATUS 3 "FINISHED" 2 "RUNNING" 1 "SELECTED" 0 "NOT SELECTED" ;
VAL_ 1296 ESTOP_REQUEST 1 "SHUTDOWN REQUESTED" 0 "NO SHUTDOWN" ;
VAL_ 1296 DIRECTION_REQUEST 2 "REVERSE" 1 "FORWARD" 0 "NEUTRAL" ;
VAL_ 1282 State_service_brake 3 "AVAILABLE" 2 "ENGAGED" 1 "DISENGAGED" ;
VAL_ 1282 State_steering 1 "ON" 0 "OFF" ;
VAL_ 1282 AMI_STATE 7 "AUTONOMOUS DEMO" 6 "STATIC INSPECTION B" 5 "STATIC INSPECTION A" 4 "TRACK DRIVE" 3 "AUTOCROSS" 2 "SKIDPAD" 1 "ACCELERATION" 0 "NOT SELECTED" ;
VAL_ 1282 State_EBS 3 "TRIGGERED" 2 "ARMED" 1 "UNAVAILABLE" ;
VAL_ 1282 State_ASSI 5 "FINISH" 4 "EMERGENCY_BRAKE" 3 "DRIVING" 2 "READY" 1 "OFF" ;
VAL_ 1316 STATUS_EBS 3 "TRIGGERED" 2 "ARMED" 1 "UNAVAILABLE" ;
VAL_ 1316 STATUS_BRK 4 "FAULT" 3 "SHUTDOWN_COMPLETE" 2 "SHUTTING_DOWN" 1 "READY" 0 "INITIALISING" ;
VAL_ 385 K3_SWITCH_STATUS 1 "ON" 0 "OFF" ;
VAL_ 385 K2_SWITCH_GO_STATUS 1 "ON" 0 "OFF" ;
VAL_ 385 ESTOP_STATUS 1 "ON" 0 "OFF" ;
VAL_ 291 BRK_DISCH_REQ 1 "TRUE" 0 "FALSE" ;
VAL_ 291 AMI_STATE 7 "AUTONOMOUS DEMO" 6 "STATIC INSPECTION B" 5 "STATIC INSPECTION A" 4 "TRACK DRIVE" 3 "AUTOCROSS" 2 "SKIDPAD" 1 "ACCELERATION" 0 "NOT SELECTED" ;
